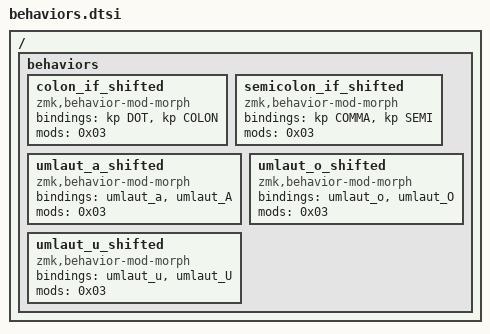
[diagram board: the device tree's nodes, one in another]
/ {
  behaviors {
    colon_if_shifted: colon_if_shifted {
      compatible = "zmk,behavior-mod-morph";
      bindings = <&kp DOT &kp COLON>;
      mods = <0x03>; // MOD_LSFT (0x01) | MOD_RSFT (0x02)
    };

    semicolon_if_shifted: semicolon_if_shifted {
      compatible = "zmk,behavior-mod-morph";
      bindings = <&kp COMMA &kp SEMI>;
      mods = <0x03>; // MOD_LSFT | MOD_RSFT
    };

    /* ───────────────  ä / Ä  ─────────────── */
    umlaut_a_shifted: umlaut_a_shifted {
      compatible = "zmk,behavior-mod-morph";
      bindings   = <&umlaut_a &umlaut_A>;
      mods       = <0x03>; // MOD_LSFT | MOD_RSFT
    };

    /* ───────────────  ö / Ö  ─────────────── */
    umlaut_o_shifted: umlaut_o_shifted {
      compatible = "zmk,behavior-mod-morph";
      bindings   = <&umlaut_o &umlaut_O>;
      mods       = <0x03>; // MOD_LSFT | MOD_RSFT
    };

    /* ───────────────  ü / Ü  ─────────────── */
    umlaut_u_shifted: umlaut_u_shifted {
      compatible = "zmk,behavior-mod-morph";
      bindings   = <&umlaut_u &umlaut_U>;
      mods       = <0x03>; // MOD_LSFT | MOD_RSFT
    };
  };
};
